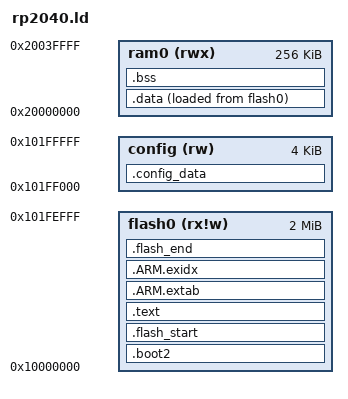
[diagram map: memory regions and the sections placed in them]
/*
 * This file was auto-generated by microzig
 *
 * Target CPU:  ARM Cortex-M0+
 * Target Chip: RP2040
 */

ENTRY(microzig_main);

MEMORY
{
  flash0 (rx!w) : ORIGIN = 0x10000000, LENGTH = 2M - 4K
  config (rw) : ORIGIN = 0x10000000 + 2M - 4K, LENGTH = 4K
  ram0   (rwx) : ORIGIN = 0x20000000, LENGTH = 0x00040000
}

SECTIONS
{
  .boot2 : {
    __boot2_start__ = .;
    KEEP (*(.boot2))
    __boot2_end__ = .;
  } > flash0

  ASSERT(__boot2_end__ - __boot2_start__ == 256,
    "ERROR: Pico second stage bootloader must be 256 bytes in size")

   .flash_start :
   {
     KEEP(*(microzig_flash_start))
   } > flash0

   .text :
   {
     *(.text*)
     *(.srodata*)
     *(.rodata*)
   } > flash0

  .ARM.extab : {
      *(.ARM.extab* .gnu.linkonce.armextab.*)
  } >flash0

  .ARM.exidx : {
      *(.ARM.exidx* .gnu.linkonce.armexidx.*)
  } >flash0

  .data :
  {
    microzig_data_start = .;
    *(.sdata*)
    *(.data*)
    KEEP(*(.ram_text))
    microzig_data_end = .;
  } > ram0 AT> flash0

  .bss (NOLOAD):
  {
    microzig_bss_start = .;
    *(.sbss*)
    *(.bss*)
    microzig_bss_end = .;
  } > ram0

  .flash_end :
  {
    microzig_flash_end = .;
  } > flash0

  .config_data : ALIGN(4)
  {
    config_data_start = .;
    . += 4096;
    config_data_end = .;
  } > config

  microzig_data_load_start = LOADADDR(.data);
}
